# AM335x register map
Vendor: Texas Instruments; Series: Sitara AM335x; File version: 1.1
AM335x EMIF4D and DDR PHY generated from EMIF.hpp
CPU: Cortex-A8 r0p0, little endian
Registers are 32-bit, read-write, reset 0x0 unless marked. A register's access mark holds for its fields unless they carry their own. Offsets are from the block's base; lines under a group give offsets from that group; [hi:lo] are bit positions; {n}, {i} and the like mark numbered series; 'fields as' and 'values as' point back to an identical list; <NAME> marks a mode.

## Memory map
0x44E00000 CM_PER — Clock Module - Peripheral
0x44E00400 CM_WKUP — Clock Module - Wakeup
0x44E00500 CM_DPLL — Clock Module - DPLL
0x44E00600 CM_MPU — Clock Module - MPU
0x44E00700 CM_DEVICE — Clock Module - Device
0x44E00800 CM_RTC — Clock Module - RTC
0x44E00900 CM_GFX — Clock Module - GFX
0x44E00A00 CM_CEFUSE — Clock Module - CEFUSE
0x44E00B00 PRM_IRQ — Power Reset Module - IRQ
0x44E00C00 PRM_PER — Power Reset Module - Peripheral
0x44E00D00 PRM_WKUP — Power Reset Module - Wakeup
0x44E00E00 PRM_MPU — Power Reset Module - MPU
0x44E00F00 PRM_DEVICE — Power Reset Module - Device
0x44E01000 PRM_RTC — Power Reset Module - RTC
0x44E01100 PRM_GFX — Power Reset Module - GFX
0x44E01200 PRM_CEFUSE — Power Reset Module - CEFUSE
0x44E07000 GPIO0 — GPIO0 module
0x44E09000 UART — UART0 module
0x44E12000 DDR23mPHY — DDR PHY Control Registers
0x4804C000 GPIO1 — GPIO1 module
0x481AC000 GPIO2 — GPIO2 module
0x481AE000 GPIO3 — GPIO3 module
0x48200000 INTC
0x49000000 EDMACC — EDMA channel controller module
0x49004000 PARAM_00 size 0x20 — PaRAM Set 00
{0x49004000+0x20*n} PARAM_{n:02} size 0x20 (n=1..63)
0x49800000 EDMATC0 — EDMA transfer controller module 0
0x49900000 EDMATC1 — EDMA transfer controller module 1
0x49A00000 EDMATC2 — EDMA transfer controller module 2
0x4C000000 EMIF0 — External Memory Interface 4D (EMIF) - DDR Controller

## INTC
Base 0x48200000
0x00 REVISION
  [7:0] Rev ro — IP revision
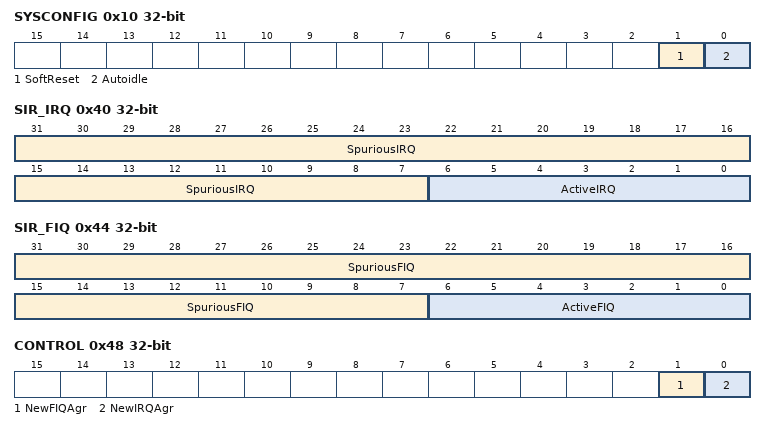
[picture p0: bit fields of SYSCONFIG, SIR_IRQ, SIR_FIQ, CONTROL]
0x10 SYSCONFIG
  [1] SoftReset — bit: 1 (RW) Software reset. [0x0 = always returns 0, 0x1 = never happens]
  [0] Autoidle — bit: 0 (RW) Internal OCP clock gating strategy [0x0 = clkfree, 0x1 = autoClkGate]
0x14 SYSSTATUS
  [0] ResetDone — bit: 0 (R) Internal reset monitoring [0x0 = reset is on-going, 0x1 = Reset completed]
0x40 SIR_IRQ
  [31:7] SpuriousIRQ — Spurious IRQ flag
  [6:0] ActiveIRQ — Active IRQ number
0x44 SIR_FIQ
  [31:7] SpuriousFIQ ro — Spurious FIQ flag
  [6:0] ActiveFIQ ro — Active FIQ number
0x48 CONTROL
  [1] NewFIQAgr — bit: 1 (W) Reset FIQ output and enable new FIQ generation [0x0 = no function effect, 0x1 = generate FIQ]
  [0] NewIRQAgr — bit: 0 (W) Reset IRQ output and enable new IRQ generation [0x0 = no function effect, 0x1 = generate IRQ]
0x4C PROTECTION
  [0] Protection — bit: 0 (RW) Protection mode [0x0 = disabled(def), 0x1 = enabled]
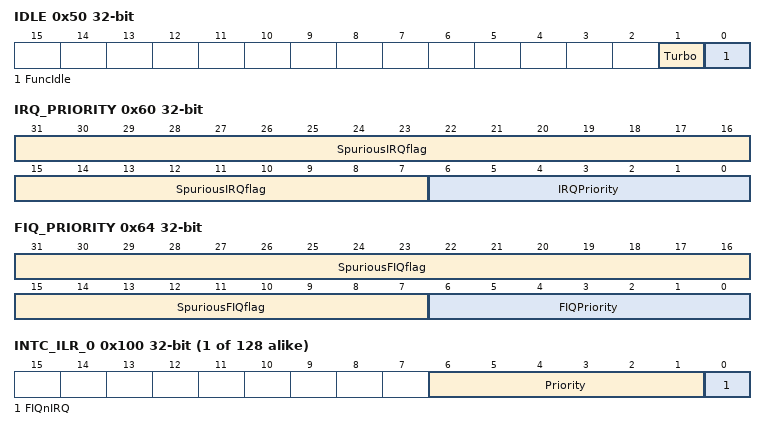
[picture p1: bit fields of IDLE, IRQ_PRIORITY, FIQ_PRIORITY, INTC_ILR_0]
0x50 IDLE
  [1] Turbo — bit: 1 (RW) Input synchroniser clock auto-gating [0x0 = is free running (default), 0x1 = generate IRQ]
  [0] FuncIdle — bit: 0 (RW) Functional clock auto-idle mode [0x0 = is applied, 0x1 = auto-gated based on interrupt input activity]
0x60 IRQ_PRIORITY
  [31:7] SpuriousIRQflag ro
  [6:0] IRQPriority ro — Current IRQ priority
0x64 FIQ_PRIORITY
  [31:7] SpuriousFIQflag ro
  [6:0] FIQPriority ro — Current FIQ priority
0x68 THRESHOLD
  [7:0] PriorityThreshold — Priority threshold. Values used are 00h to 3Fh. Value FFh disables the threshold.
{0x80+0x20*i} ITR{i} (i=0..3) — ITR Register
  [31:0] Itr ro — Interrupt status before masking
{0x84+0x20*i} MIR{i} (i=0..3) — MIR Register
  [31:0] Mir — Interrupt mask
{0x88+0x20*i} MIR_CLEAR{i} (i=0..3) — MIR_CLEAR Register
  [31:0] MirClear wo — Write 1 clears the mask bit to 0, reads return 0
{0x8C+0x20*i} MIR_SET{i} (i=0..3) — MIR_SET Register
  [31:0] MirSet wo — Write 1 sets the mask bit to 1, reads return 0
{0x90+0x20*i} ISR_SET{i} (i=0..3) — ISR_SET Register
  [31:0] IsrSet — Reads returns the currently active software interrupts, Write 1 sets the software interrupt bits to 1
{0x94+0x20*i} ISR_CLEAR{i} (i=0..3) — ISR_CLEAR Register
  [31:0] IsrClear wo — Write 1 clears the software interrupt bits to 0, reads return 0
{0x98+0x20*i} PENDING_IRQ{i} (i=0..3) — PENDING_IRQ Register
  [31:0] PendingIRQ ro — IRQ status after masking
{0x9C+0x20*i} PENDING_FIQ{i} (i=0..3) — PENDING_FIQ Register
  [31:0] PendingFIQ ro — FIQ status after masking
{0x100+4i} INTC_ILR_{i} (i=0..127) — INTC_ILR Register
  [6:1] Priority — Interrupt priority
  [0] FIQnIRQ — bit: 0 (RW) Interrupt IRQ FiQ mapping [0x0 = Interrupt is routed to IRQ, 0x1 = Interrupt is routed to FIQ]
